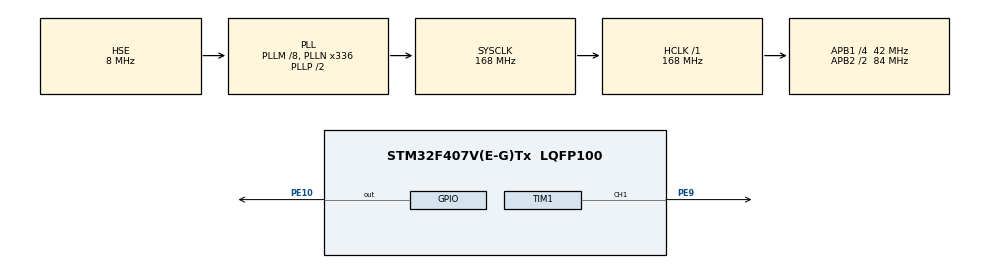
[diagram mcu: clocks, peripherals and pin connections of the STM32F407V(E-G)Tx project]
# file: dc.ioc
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Mcu.Family=STM32F4
Mcu.Name=STM32F407V(E-G)Tx
Mcu.Package=LQFP100
NVIC.PriorityGroup=NVIC_PRIORITYGROUP_4
NVIC.TIM6_DAC_IRQn=true\:0\:0\:false\:false\:true\:true\:true
PA13.Mode=Serial_Wire
PA13.Signal=SYS_JTMS-SWDIO
PA14.Mode=Serial_Wire
PA14.Signal=SYS_JTCK-SWCLK
PE10.GPIO_Speed=GPIO_SPEED_FREQ_VERY_HIGH
PE10.Signal=GPIO_Output
PE9.GPIO_ModeDefaultPP=GPIO_MODE_AF_PP
PE9.GPIO_PuPd=GPIO_NOPULL
PE9.GPIO_Speed=GPIO_SPEED_FREQ_HIGH
PE9.Signal=S_TIM1_CH1
PH0-OSC_IN.Mode=HSE-External-Oscillator
PH0-OSC_IN.Signal=RCC_OSC_IN
PH1-OSC_OUT.Mode=HSE-External-Oscillator
PH1-OSC_OUT.Signal=RCC_OSC_OUT
ProjectManager.HeapSize=0x200
ProjectManager.StackSize=0x400
ProjectManager.TargetToolchain=EWARM V7
RCC.48MHZClocksFreq_Value=84000000
RCC.AHBFreq_Value=168000000
RCC.APB1CLKDivider=RCC_HCLK_DIV4
RCC.APB1Freq_Value=42000000
RCC.APB1TimFreq_Value=84000000
RCC.APB2CLKDivider=RCC_HCLK_DIV2
RCC.APB2Freq_Value=84000000
RCC.APB2TimFreq_Value=168000000
RCC.CortexFreq_Value=168000000
RCC.HCLKFreq_Value=168000000
RCC.HSE_VALUE=8000000
RCC.HSI_VALUE=16000000
RCC.LSE_VALUE=32768
RCC.PLLM=8
RCC.PLLN=336
RCC.PLLSourceVirtual=RCC_PLLSOURCE_HSE
RCC.SYSCLKFreq_VALUE=168000000
RCC.SYSCLKSource=RCC_SYSCLKSOURCE_PLLCLK
RCC.VCOOutputFreq_Value=336000000
SH.S_TIM1_CH1.0=TIM1_CH1,PWM Generation1 CH1
TIM1.Channel-PWM\ Generation1\ CH1=TIM_CHANNEL_1
TIM1.Period=1000
TIM1.Prescaler=8
TIM6.Period=999
TIM6.Prescaler=84
VP_TIM1_VS_ClockSourceINT.Mode=Internal
VP_TIM6_VS_ClockSourceINT.Mode=Enable_Timer
board=dc

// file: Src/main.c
/* USER CODE BEGIN Header */
/**
  ******************************************************************************
  * @file           : main.c
  * @brief          : Main program body
  ******************************************************************************
  * @attention
  *
  * <h2><center>&copy; Copyright (c) 2021 STMicroelectronics.
  * All rights reserved.</center></h2>
  *
  * This software component is licensed by ST under BSD 3-Clause license,
  * the "License"; You may not use this file except in compliance with the
  * License. You may obtain a copy of the License at:
  *                        opensource.org/licenses/BSD-3-Clause
  *
  ******************************************************************************
  */
/* USER CODE END Header */
#include "main.h"

TIM_HandleTypeDef htim1;
TIM_HandleTypeDef htim6;

/* USER CODE BEGIN PV */
/* Private variables ---------------------------------------------------------*/

/* USER CODE END PV */

void SystemClock_Config(void);
static void MX_GPIO_Init(void);
static void MX_TIM1_Init(void);
static void MX_TIM6_Init(void);
/* USER CODE BEGIN PFP */
/* Private function prototypes -----------------------------------------------*/

/* USER CODE END PFP */

/* USER CODE BEGIN 0 */
uint16_t  div=0,   giatri=200 ,giatrisau;

 void HAL_TIM_PeriodElapsedCallback(TIM_HandleTypeDef *htim)//so sanh timer
 {
   if (htim->Instance== htim6.Instance)
 {
    if(giatri>giatrisau){
        giatrisau++;
      }
      if(giatri<giatrisau){
        giatrisau--;
      }

       __HAL_TIM_SET_COMPARE(&htim1,TIM_CHANNEL_1,giatrisau);
 }
 }

/* USER CODE END 0 */

int main(void)
{

  /* MCU Configuration--------------------------------------------------------*/

  /* Reset of all peripherals, Initializes the Flash interface and the Systick. */
  HAL_Init();

  /* Configure the system clock */
  SystemClock_Config();

  /* Initialize all configured peripherals */
  MX_GPIO_Init();
  MX_TIM1_Init();
  MX_TIM6_Init();
  /* USER CODE BEGIN 2 */
 HAL_TIM_Base_Start_IT(&htim6);
HAL_TIM_PWM_Start (&htim1,TIM_CHANNEL_1);
  /* USER CODE END 2 */

  /* Infinite loop */
  while (1)
  {

    /* USER CODE BEGIN 3 */
    if (div==0){
      HAL_GPIO_WritePin(GPIOE,GPIO_PIN_10,GPIO_PIN_RESET);

  }
  if (div==1){
  HAL_GPIO_WritePin(GPIOE,GPIO_PIN_10,GPIO_PIN_SET);

  }
  }
  /* USER CODE END 3 */
}

void SystemClock_Config(void)
{
  RCC_OscInitTypeDef RCC_OscInitStruct = {0};
  RCC_ClkInitTypeDef RCC_ClkInitStruct = {0};

  /** Configure the main internal regulator output voltage
  */
  __HAL_RCC_PWR_CLK_ENABLE();
  __HAL_PWR_VOLTAGESCALING_CONFIG(PWR_REGULATOR_VOLTAGE_SCALE1);
  /** Initializes the RCC Oscillators according to the specified parameters
  * in the RCC_OscInitTypeDef structure.
  */
  RCC_OscInitStruct.OscillatorType = RCC_OSCILLATORTYPE_HSE;
  RCC_OscInitStruct.HSEState = RCC_HSE_ON;
  RCC_OscInitStruct.PLL.PLLState = RCC_PLL_ON;
  RCC_OscInitStruct.PLL.PLLSource = RCC_PLLSOURCE_HSE;
  RCC_OscInitStruct.PLL.PLLM = 8;
  RCC_OscInitStruct.PLL.PLLN = 336;
  RCC_OscInitStruct.PLL.PLLP = RCC_PLLP_DIV2;
  RCC_OscInitStruct.PLL.PLLQ = 4;
  if (HAL_RCC_OscConfig(&RCC_OscInitStruct) != HAL_OK)
  {
    Error_Handler();
  }
  /** Initializes the CPU, AHB and APB buses clocks
  */
  RCC_ClkInitStruct.ClockType = RCC_CLOCKTYPE_HCLK|RCC_CLOCKTYPE_SYSCLK
                              |RCC_CLOCKTYPE_PCLK1|RCC_CLOCKTYPE_PCLK2;
  RCC_ClkInitStruct.SYSCLKSource = RCC_SYSCLKSOURCE_PLLCLK;
  RCC_ClkInitStruct.AHBCLKDivider = RCC_SYSCLK_DIV1;
  RCC_ClkInitStruct.APB1CLKDivider = RCC_HCLK_DIV4;
  RCC_ClkInitStruct.APB2CLKDivider = RCC_HCLK_DIV2;

  if (HAL_RCC_ClockConfig(&RCC_ClkInitStruct, FLASH_LATENCY_5) != HAL_OK)
  {
    Error_Handler();
  }
}

static void MX_TIM1_Init(void)
{

  TIM_ClockConfigTypeDef sClockSourceConfig = {0};
  TIM_MasterConfigTypeDef sMasterConfig = {0};
  TIM_OC_InitTypeDef sConfigOC = {0};
  TIM_BreakDeadTimeConfigTypeDef sBreakDeadTimeConfig = {0};

  htim1.Instance = TIM1;
  htim1.Init.Prescaler = 8;
  htim1.Init.CounterMode = TIM_COUNTERMODE_UP;
  htim1.Init.Period = 1000;
  htim1.Init.ClockDivision = TIM_CLOCKDIVISION_DIV1;
  htim1.Init.RepetitionCounter = 0;
  htim1.Init.AutoReloadPreload = TIM_AUTORELOAD_PRELOAD_DISABLE;
  if (HAL_TIM_Base_Init(&htim1) != HAL_OK)
  {
    Error_Handler();
  }
  sClockSourceConfig.ClockSource = TIM_CLOCKSOURCE_INTERNAL;
  if (HAL_TIM_ConfigClockSource(&htim1, &sClockSourceConfig) != HAL_OK)
  {
    Error_Handler();
  }
  if (HAL_TIM_PWM_Init(&htim1) != HAL_OK)
  {
    Error_Handler();
  }
  sMasterConfig.MasterOutputTrigger = TIM_TRGO_RESET;
  sMasterConfig.MasterSlaveMode = TIM_MASTERSLAVEMODE_DISABLE;
  if (HAL_TIMEx_MasterConfigSynchronization(&htim1, &sMasterConfig) != HAL_OK)
  {
    Error_Handler();
  }
  sConfigOC.OCMode = TIM_OCMODE_PWM1;
  sConfigOC.Pulse = 0;
  sConfigOC.OCPolarity = TIM_OCPOLARITY_HIGH;
  sConfigOC.OCNPolarity = TIM_OCNPOLARITY_HIGH;
  sConfigOC.OCFastMode = TIM_OCFAST_DISABLE;
  sConfigOC.OCIdleState = TIM_OCIDLESTATE_RESET;
  sConfigOC.OCNIdleState = TIM_OCNIDLESTATE_RESET;
  if (HAL_TIM_PWM_ConfigChannel(&htim1, &sConfigOC, TIM_CHANNEL_1) != HAL_OK)
  {
    Error_Handler();
  }
  sBreakDeadTimeConfig.OffStateRunMode = TIM_OSSR_DISABLE;
  sBreakDeadTimeConfig.OffStateIDLEMode = TIM_OSSI_DISABLE;
  sBreakDeadTimeConfig.LockLevel = TIM_LOCKLEVEL_OFF;
  sBreakDeadTimeConfig.DeadTime = 0;
  sBreakDeadTimeConfig.BreakState = TIM_BREAK_DISABLE;
  sBreakDeadTimeConfig.BreakPolarity = TIM_BREAKPOLARITY_HIGH;
  sBreakDeadTimeConfig.AutomaticOutput = TIM_AUTOMATICOUTPUT_DISABLE;
  if (HAL_TIMEx_ConfigBreakDeadTime(&htim1, &sBreakDeadTimeConfig) != HAL_OK)
  {
    Error_Handler();
  }
  HAL_TIM_MspPostInit(&htim1);

}

static void MX_TIM6_Init(void)
{

  TIM_MasterConfigTypeDef sMasterConfig = {0};

  htim6.Instance = TIM6;
  htim6.Init.Prescaler = 84;
  htim6.Init.CounterMode = TIM_COUNTERMODE_UP;
  htim6.Init.Period = 999;
  htim6.Init.AutoReloadPreload = TIM_AUTORELOAD_PRELOAD_DISABLE;
  if (HAL_TIM_Base_Init(&htim6) != HAL_OK)
  {
    Error_Handler();
  }
  sMasterConfig.MasterOutputTrigger = TIM_TRGO_RESET;
  sMasterConfig.MasterSlaveMode = TIM_MASTERSLAVEMODE_DISABLE;
  if (HAL_TIMEx_MasterConfigSynchronization(&htim6, &sMasterConfig) != HAL_OK)
  {
    Error_Handler();
  }

}

static void MX_GPIO_Init(void)
{
  GPIO_InitTypeDef GPIO_InitStruct = {0};

  /* GPIO Ports Clock Enable */
  __HAL_RCC_GPIOH_CLK_ENABLE();
  __HAL_RCC_GPIOE_CLK_ENABLE();
  __HAL_RCC_GPIOA_CLK_ENABLE();

  /*Configure GPIO pin Output Level */
  HAL_GPIO_WritePin(GPIOE, GPIO_PIN_10, GPIO_PIN_RESET);

  /*Configure GPIO pin : PE10 */
  GPIO_InitStruct.Pin = GPIO_PIN_10;
  GPIO_InitStruct.Mode = GPIO_MODE_OUTPUT_PP;
  GPIO_InitStruct.Pull = GPIO_NOPULL;
  GPIO_InitStruct.Speed = GPIO_SPEED_FREQ_VERY_HIGH;
  HAL_GPIO_Init(GPIOE, &GPIO_InitStruct);

}

void Error_Handler(void)
{
  while(1)
  {
  }
}

/************************ (C) COPYRIGHT STMicroelectronics *****END OF FILE****/
